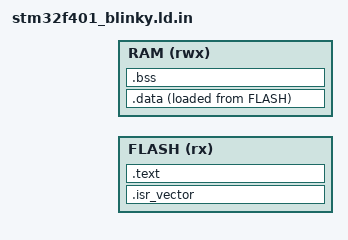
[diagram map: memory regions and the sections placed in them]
MEMORY
{
    FLASH (rx) : ORIGIN = @TRISHUL_STM32_FLASH_ORIGIN@, LENGTH = @TRISHUL_STM32_FLASH_LENGTH@
    RAM (rwx)  : ORIGIN = @TRISHUL_STM32_RAM_ORIGIN@, LENGTH = @TRISHUL_STM32_RAM_LENGTH@
}

ENTRY(Reset_Handler)

__stack_top = ORIGIN(RAM) + LENGTH(RAM);

SECTIONS
{
    .isr_vector :
    {
        KEEP(*(.isr_vector))
    } > FLASH

    .text :
    {
        *(.text*)
        *(.rodata*)
        . = ALIGN(4);
    } > FLASH

    .data :
    {
        __data_start__ = .;
        *(.data*)
        . = ALIGN(4);
        __data_end__ = .;
    } > RAM AT > FLASH
    __data_load_start__ = LOADADDR(.data);

    .bss (NOLOAD) :
    {
        __bss_start__ = .;
        *(.bss*)
        *(COMMON)
        . = ALIGN(4);
        __bss_end__ = .;
    } > RAM
}
